AUTOSAR XML (schema 4-0-3)
package /ComponentTypes
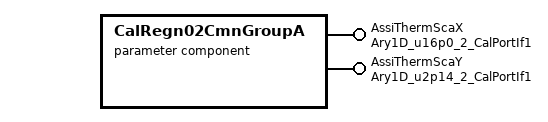
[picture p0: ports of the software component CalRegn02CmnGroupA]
  parameter sw component type CalRegn02CmnGroupA
    provide port AssiThermScaX: parameter-provide-com-spec{init-value=[75, 100], parameter=Ary1D}, provided-interface=Ary1D_u16p0_2_CalPortIf1
    provide port AssiThermScaY: parameter-provide-com-spec{init-value=[16384, 13107], parameter=Ary1D}, provided-interface=Ary1D_u2p14_2_CalPortIf1
